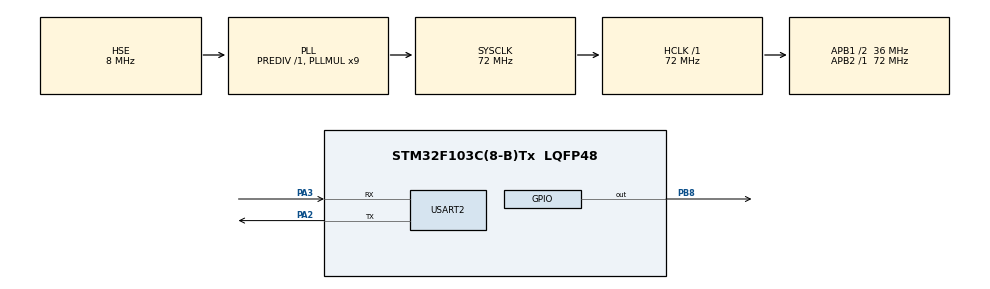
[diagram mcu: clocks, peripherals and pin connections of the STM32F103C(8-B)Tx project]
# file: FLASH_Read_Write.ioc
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Dma.Request0=USART2_RX
Dma.USART2_RX.0.Direction=DMA_PERIPH_TO_MEMORY
Dma.USART2_RX.0.Instance=DMA1_Channel6
Dma.USART2_RX.0.MemDataAlignment=DMA_MDATAALIGN_BYTE
Dma.USART2_RX.0.MemInc=DMA_MINC_ENABLE
Dma.USART2_RX.0.Mode=DMA_CIRCULAR
Dma.USART2_RX.0.PeriphDataAlignment=DMA_PDATAALIGN_BYTE
Dma.USART2_RX.0.PeriphInc=DMA_PINC_DISABLE
Dma.USART2_RX.0.Priority=DMA_PRIORITY_LOW
Mcu.Family=STM32F1
Mcu.Name=STM32F103C(8-B)Tx
Mcu.Package=LQFP48
NVIC.DMA1_Channel6_IRQn=true\:0\:0\:false\:false\:true\:false\:true
NVIC.FLASH_IRQn=true\:0\:0\:false\:false\:true\:true\:true
NVIC.PriorityGroup=NVIC_PRIORITYGROUP_4
NVIC.USART2_IRQn=true\:0\:0\:false\:false\:true\:true\:true
PA13.Mode=Serial_Wire
PA13.Signal=SYS_JTMS-SWDIO
PA14.Mode=Serial_Wire
PA14.Signal=SYS_JTCK-SWCLK
PA2.Mode=Asynchronous
PA2.Signal=USART2_TX
PA3.Mode=Asynchronous
PA3.Signal=USART2_RX
PB8.Signal=GPIO_Output
PD0-OSC_IN.Mode=HSE-External-Oscillator
PD0-OSC_IN.Signal=RCC_OSC_IN
PD1-OSC_OUT.Mode=HSE-External-Oscillator
PD1-OSC_OUT.Signal=RCC_OSC_OUT
ProjectManager.HeapSize=0x200
ProjectManager.StackSize=0x400
ProjectManager.TargetToolchain=STM32CubeIDE
RCC.AHBFreq_Value=72000000
RCC.APB1CLKDivider=RCC_HCLK_DIV2
RCC.APB1Freq_Value=36000000
RCC.APB1TimFreq_Value=72000000
RCC.APB2Freq_Value=72000000
RCC.APB2TimFreq_Value=72000000
RCC.HCLKFreq_Value=72000000
RCC.PLLMUL=RCC_PLL_MUL9
RCC.PLLSourceVirtual=RCC_PLLSOURCE_HSE
RCC.SYSCLKFreq_VALUE=72000000
RCC.SYSCLKSource=RCC_SYSCLKSOURCE_PLLCLK
RCC.USBFreq_Value=72000000
USART2.VirtualMode=VM_ASYNC
board=custom

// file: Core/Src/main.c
/* USER CODE BEGIN Header */
/**
 ******************************************************************************
 * @file           : main.c
 * @brief          : Main program body
 ******************************************************************************
 * @attention
 *
 * <h2><center>&copy; Copyright (c) 2020 STMicroelectronics.
 * All rights reserved.</center></h2>
 *
 * This software component is licensed by ST under BSD 3-Clause license,
 * the "License"; You may not use this file except in compliance with the
 * License. You may obtain a copy of the License at:
 *                        opensource.org/licenses/BSD-3-Clause
 *
 ******************************************************************************
 */
/* USER CODE END Header */
#include <stdint.h>
#include "main.h"
#include "dma.h"
#include "usart.h"
#include "gpio.h"
/* USER CODE BEGIN Includes */
#include "myFlash.h"
#include "myLib.h"
/* USER CODE END Includes */

/**
 * @brief Page number x has start_address = 1024*x
 *
 */

/* USER CODE BEGIN PV */
uint32_t data[] = {22, 12, 1998, 1, 2, 3, 4, 5, 6};
/* USER CODE END PV */

void SystemClock_Config(void);

int main(void)
{

  /* MCU Configuration--------------------------------------------------------*/

  /* Reset of all peripherals, Initializes the Flash interface and the Systick. */
  HAL_Init();

  /* Configure the system clock */
  SystemClock_Config();

  /* Initialize all configured peripherals */
  MX_GPIO_Init();
  MX_DMA_Init();
  MX_USART2_UART_Init();
  /* USER CODE BEGIN 2 */

  PRINTF("################################################################################################\r\n");
  PRINTF("Project name: [FLASH]ReadWrite_internal_flash\r\n");
  PRINTF("**********************************SHORT DESCRIPTION******************************\r\n");
  PRINTF("This project illustrate how to write data to internal flash as well as Read out Flash data\r\n");
  PRINTF("*********************************************************************************\r\n");
  PRINTF("Run Application\r\n");

  PRINTF("\r\nStart writing data to internal Flash\r\n");
  Flash_WriteWord(ADDR_FLASH_PAGE_50, FLASH_END_ADDRESS, data, sizeof(data) / 4);

  PRINTF("\r\nVerify written data\r\n");
  for (size_t i = 0; i < sizeof(data) / 4; i++)
  {
    printVar(Flash_ReadAddress(ADDR_FLASH_PAGE_50 + i * 4));
  }

  /* USER CODE END 2 */

  /* Infinite loop */
  while (1)
  {
    toggleLed4;
    HAL_Delay(1000);
  }
}

void SystemClock_Config(void)
{
  RCC_OscInitTypeDef RCC_OscInitStruct = {0};
  RCC_ClkInitTypeDef RCC_ClkInitStruct = {0};

  /** Initializes the RCC Oscillators according to the specified parameters
     * in the RCC_OscInitTypeDef structure.
     */
  RCC_OscInitStruct.OscillatorType = RCC_OSCILLATORTYPE_HSE;
  RCC_OscInitStruct.HSEState = RCC_HSE_ON;
  RCC_OscInitStruct.HSEPredivValue = RCC_HSE_PREDIV_DIV1;
  RCC_OscInitStruct.HSIState = RCC_HSI_ON;
  RCC_OscInitStruct.PLL.PLLState = RCC_PLL_ON;
  RCC_OscInitStruct.PLL.PLLSource = RCC_PLLSOURCE_HSE;
  RCC_OscInitStruct.PLL.PLLMUL = RCC_PLL_MUL9;
  if (HAL_RCC_OscConfig(&RCC_OscInitStruct) != HAL_OK)
  {
    Error_Handler();
  }
  /** Initializes the CPU, AHB and APB buses clocks
     */
  RCC_ClkInitStruct.ClockType = RCC_CLOCKTYPE_HCLK | RCC_CLOCKTYPE_SYSCLK | RCC_CLOCKTYPE_PCLK1 | RCC_CLOCKTYPE_PCLK2;
  RCC_ClkInitStruct.SYSCLKSource = RCC_SYSCLKSOURCE_PLLCLK;
  RCC_ClkInitStruct.AHBCLKDivider = RCC_SYSCLK_DIV1;
  RCC_ClkInitStruct.APB1CLKDivider = RCC_HCLK_DIV2;
  RCC_ClkInitStruct.APB2CLKDivider = RCC_HCLK_DIV1;

  if (HAL_RCC_ClockConfig(&RCC_ClkInitStruct, FLASH_LATENCY_2) != HAL_OK)
  {
    Error_Handler();
  }
}

void Error_Handler(void)
{
}

/************************ (C) COPYRIGHT STMicroelectronics *****END OF FILE****/
